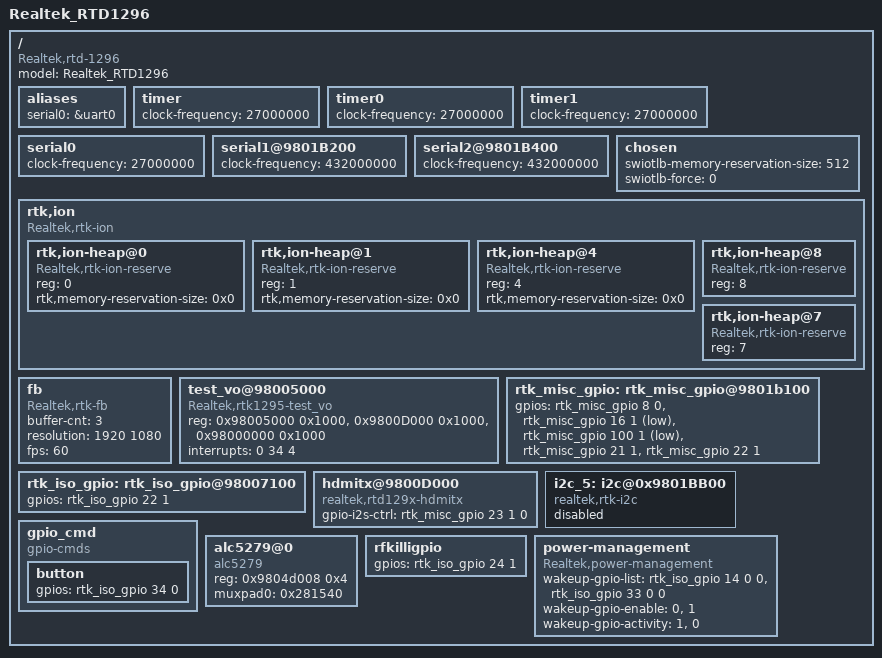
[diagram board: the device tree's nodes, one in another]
#include "rtd-1296.dtsi"

/ {
	model= "Realtek_RTD1296";
	compatible = "Realtek,rtd-1296";

	aliases {
		serial0 = &uart0;
	};

	timer {
		clock-frequency = <27000000>;
	};

	timer0 {
		clock-frequency = <27000000>;
	};

	timer1 {
		clock-frequency = <27000000>;
	};

	serial0 {
		clock-frequency = <27000000>;
	};

	serial1@9801B200 {
		clock-frequency = <432000000>;
	};

	serial2@9801B400 {
		clock-frequency = <432000000>;
	};

	chosen {
		swiotlb-memory-reservation-size = <512>;
		swiotlb-force = <0>;
	};

	rtk,ion {
		compatible = "Realtek,rtk-ion";
		#address-cells = <1>;
		#size-cells = <0>;

		rtk,ion-heap@0 { /* SYSTEM_HEAP */
			compatible = "Realtek,rtk-ion-reserve";
			reg = <0>;
			rtk,memory-reservation-size = <0x0>;
		};

		rtk,ion-heap@1 { /* System contig */
			compatible = "Realtek,rtk-ion-reserve";
			reg = <1>;
			rtk,memory-reservation-size = <0x0>;
		};

		rtk,ion-heap@4 { /* DMA_HEAP */
			compatible = "Realtek,rtk-ion-reserve";
			reg = <4>;
			rtk,memory-reservation-size = <0x0>;
		};

		rtk,ion-heap@8 { /* Audio */
			compatible = "Realtek,rtk-ion-reserve";
			reg = <8>;
		};

		rtk,ion-heap@7 { /* TYPE_MEDIA */
			compatible = "Realtek,rtk-ion-reserve";
			reg = <7>;
		};
	};

	fb {
		compatible = "Realtek,rtk-fb";
		buffer-cnt = <3>;
		resolution = <1920 1080>;
		fps = <60>;
	};

	test_vo@98005000 {
		compatible = "Realtek,rtk1295-test_vo";
		reg = <0x98005000 0x1000>,
			<0x9800D000 0x1000>,
			<0x98000000 0x1000>;
		interrupts = <0 34 4>;
	};

	rtk_misc_gpio: rtk_misc_gpio@9801b100 {
		gpios = <&rtk_misc_gpio 8 0 0>, /* install button */
			<&rtk_misc_gpio 16 1 1>, /* HV_EN, enable regulator */
			<&rtk_misc_gpio 100 1 1>, /* audio dac unmute */
			<&rtk_misc_gpio 21 1 0>, /* LED*/
			<&rtk_misc_gpio 22 1 0>; /* LED*/
	};

	rtk_iso_gpio: rtk_iso_gpio@98007100 {
		gpios =<&rtk_iso_gpio 22 1 0>; /* LED */
	};

	hdmitx@9800D000 {
		compatible = "realtek,rtd129x-hdmitx";
		gpio-i2s-ctrl = <&rtk_misc_gpio 23 1 0>; /* I2S output control */
	};

	i2c_5: i2c@0x9801BB00 {
		compatible = "realtek,rtk-i2c";
		status = "disabled"; /* disable rts5400 */
	};

	gpio_cmd {
		compatible = "gpio-cmds";

		/*5679_gpio2 =
			<&rtk_misc_gpio 18 0 0>; /* 5679_GPIO2 */
		/*5679_gpio3 =
			<&rtk_misc_gpio 54 0 0>; /* 5679_GPIO3 */
		/*5679_gpio12 =
			<&rtk_misc_gpio 61 0 0>; /* 5679_GPIO12 */
		/*5679_gpio13 =
			<&rtk_misc_gpio 62 0 0>; /* 5679_GPIO13 */
		/*5679_ldo =
			<&rtk_misc_gpio 23 0 1>; /* 5679_LDO */

		status = "okay";

		button {
			gpios = <&rtk_iso_gpio 34 0 0>; /* igpio34, ALc_IRQ */
		};
	};

	 alc5279@0 {
		compatible = "alc5279";
		reg	 = <0x9804d008 0x4>; /* DISP_MUXPAD0 */
		muxpad0 = <0x281540>;
		status  = "okay";
	};

	rfkilligpio {
		gpios = <&rtk_iso_gpio 24 1 0>; /*bt power */
		status = "okay";
	};

	/*
	 * Suspend GPIO control
	 *
	 * [wakeup-gpio-list]
	 * rtk_iso_gpio 14: BT wakeup host pin
	 * rtk_iso_gpio 33: WiFi wakeup host pin
	 *
	 * [wakeup-gpio-enable]
	 * Wakeup from BT: <0>disabele
	 * Wakeup from WiFi: <1> enable
	 *
	 * [wakeup-gpio-activity]
	 * BT pin: <1>active high
	 * WIFI pin: <0>active low
	 */
	power-management {
		compatible = "Realtek,power-management";
		wakeup-gpio-list = <&rtk_iso_gpio 14 0 0>,
			<&rtk_iso_gpio 33 0 0>;
		wakeup-gpio-enable = <0>, <1>;
		wakeup-gpio-activity = <1>, <0>;
	};
};

